# RX64M_SCIFA_Pilot register map
File version: 1.0
RX64M_SCIFA_Pilot peripheral registers generated from iodefine.h (pilot).
Registers are 16-bit, read-write, reset 0x0 unless marked. A register's access mark holds for its fields unless they carry their own. Offsets are from the block's base; lines under a group give offsets from that group; [hi:lo] are bit positions; {n}, {i} and the like mark numbered series; 'fields as' and 'values as' point back to an identical list; <NAME> marks a mode.

## Memory map
0x000D0000 SCIFA8 size 0x18
0x000D0020 SCIFA9 size 0x18
0x000D0040 SCIFA10 size 0x18
0x000D0060 SCIFA11 size 0x18

## SCIFA8
Base 0x000D0000
Same registers: SCIFA9 0x000D0020, SCIFA10 0x000D0040, SCIFA11 0x000D0060
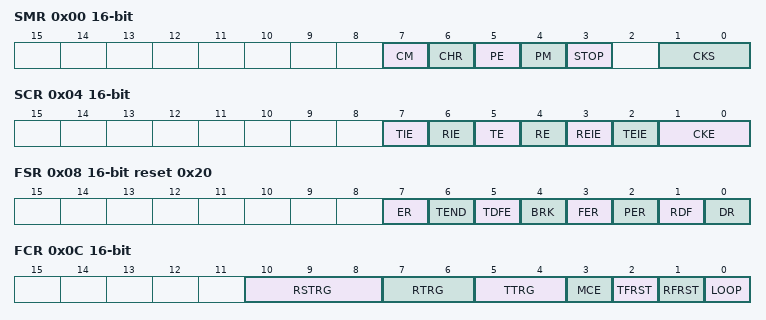
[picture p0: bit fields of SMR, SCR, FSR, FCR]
0x00 SMR
  [7] CM, [6] CHR, [5] PE, [4] PM, [3] STOP, [1:0] CKS
0x02 BRR 8-bit reset 0xFF
0x02 MDDR 8-bit reset 0xFF (alternate view of BRR)
0x04 SCR
  [7] TIE, [6] RIE, [5] TE, [4] RE, [3] REIE, [2] TEIE, [1:0] CKE
0x06 FTDR 8-bit wo reset 0xFF
0x08 FSR reset 0x20
  [7] ER, [6] TEND, [5] TDFE, [4] BRK, [3] FER, [2] PER, [1] RDF, [0] DR
0x0A FRDR 8-bit ro
0x0C FCR
  [10:8] RSTRG, [7:6] RTRG, [5:4] TTRG, [3] MCE, [2] TFRST, [1] RFRST, [0] LOOP
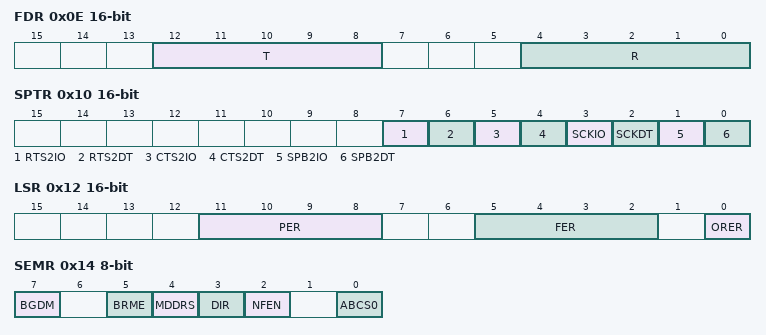
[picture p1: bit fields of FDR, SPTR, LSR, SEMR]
0x0E FDR
  [12:8] T, [4:0] R
0x10 SPTR (reset mask 0xFFAA)
  [7] RTS2IO, [6] RTS2DT, [5] CTS2IO, [4] CTS2DT, [3] SCKIO, [2] SCKDT, [1] SPB2IO, [0] SPB2DT
0x12 LSR
  [11:8] PER, [5:2] FER, [0] ORER
0x14 SEMR 8-bit
  [7] BGDM, [5] BRME, [4] MDDRS, [3] DIR, [2] NFEN, [0] ABCS0
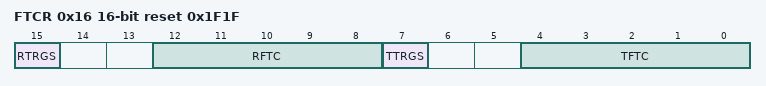
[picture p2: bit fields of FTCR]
0x16 FTCR reset 0x1F1F
  [15] RTRGS, [12:8] RFTC, [7] TTRGS, [4:0] TFTC
